# ATSAMR34J17B device description
Architecture: CORTEX-M0PLUS; Family: SAMR; Series: SAMR34
Registers are 32-bit, read-write, reset 0x0 unless marked. A register's access mark holds for its fields unless they carry their own. Offsets are from the block's base; [hi:lo] are bit positions; {n}, {i} and the like mark numbered series.

## PAC — Peripheral Access Controller
Instances: PAC 0x44000000
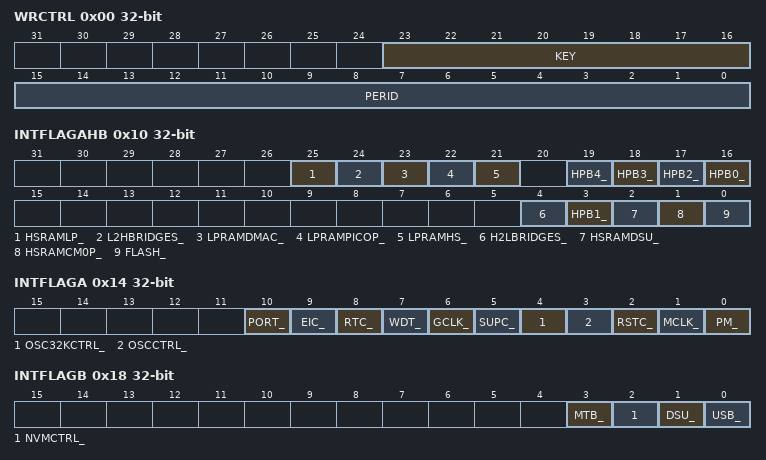
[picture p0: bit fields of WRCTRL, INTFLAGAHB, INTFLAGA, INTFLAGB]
0x00 WRCTRL — Write control
  [23:16] KEY — Peripheral access control key
    0=OFF (No action); 1=CLR (Clear protection); 2=SET (Set protection); 3=SETLCK (Set and lock protection)
  [15:0] PERID — Peripheral identifier
0x04 EVCTRL 8-bit — Event control
  [0] ERREO — Peripheral acess error event output
0x08 INTENCLR 8-bit (atomic clear) — Interrupt enable clear
  [0] ERR — Peripheral access error interrupt disable
0x09 INTENSET 8-bit (atomic set) — Interrupt enable set
  [0] ERR — Peripheral access error interrupt enable
0x10 INTFLAGAHB (atomic clear) — Bridge interrupt flag status
  [25] HSRAMLP_, [24] L2HBRIDGES_, [23] LPRAMDMAC_, [22] LPRAMPICOP_, [21] LPRAMHS_, [19] HPB4_, [18] HPB3_, [17] HPB2_, [16] HPB0_, [4] H2LBRIDGES_, [3] HPB1_, [2] HSRAMDSU_, [1] HSRAMCM0P_, [0] FLASH_
0x14 INTFLAGA (atomic clear) — Peripheral interrupt flag status - Bridge A
  [10] PORT_, [9] EIC_, [8] RTC_, [7] WDT_, [6] GCLK_, [5] SUPC_, [4] OSC32KCTRL_, [3] OSCCTRL_, [2] RSTC_, [1] MCLK_, [0] PM_
0x18 INTFLAGB (atomic clear) — Peripheral interrupt flag status - Bridge B
  [3] MTB_, [2] NVMCTRL_, [1] DSU_, [0] USB_
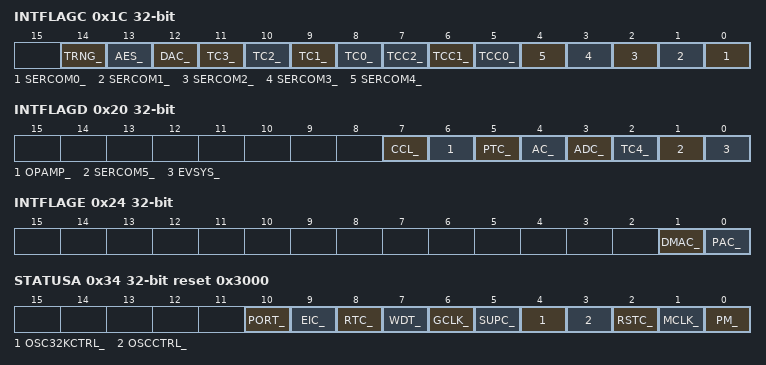
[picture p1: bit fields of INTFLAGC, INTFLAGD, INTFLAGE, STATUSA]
0x1C INTFLAGC (atomic clear) — Peripheral interrupt flag status - Bridge C
  [14] TRNG_, [13] AES_, [12] DAC_, [n+8] TC{n}_ (n=0..3), [7] TCC2_, [6] TCC1_, [5] TCC0_, [n] SERCOM{n}_ (n=0..4)
0x20 INTFLAGD (atomic clear) — Peripheral interrupt flag status - Bridge D
  [7] CCL_, [6] OPAMP_, [5] PTC_, [4] AC_, [3] ADC_, [2] TC4_, [1] SERCOM5_, [0] EVSYS_
0x24 INTFLAGE (atomic clear) — Peripheral interrupt flag status - Bridge E
  [1] DMAC_, [0] PAC_
0x34 STATUSA ro reset 0x3000 — Peripheral write protection status - Bridge A
  [10] PORT_ — PORT APB Protect Enable
  [9] EIC_ — EIC APB Protect Enable
  [8] RTC_ — RTC APB Protect Enable
  [7] WDT_ — WDT APB Protect Enable
  [6] GCLK_ — GCLK APB Protect Enable
  [5] SUPC_ — SUPC APB Protect Enable
  [4] OSC32KCTRL_ — OSC32KCTRL APB Protect Enable
  [3] OSCCTRL_ — OSCCTRL APB Protect Enable
  [2] RSTC_ — RSTC APB Protect Enable
  [1] MCLK_ — MCLK APB Protect Enable
  [0] PM_ — PM APB Protect Enable
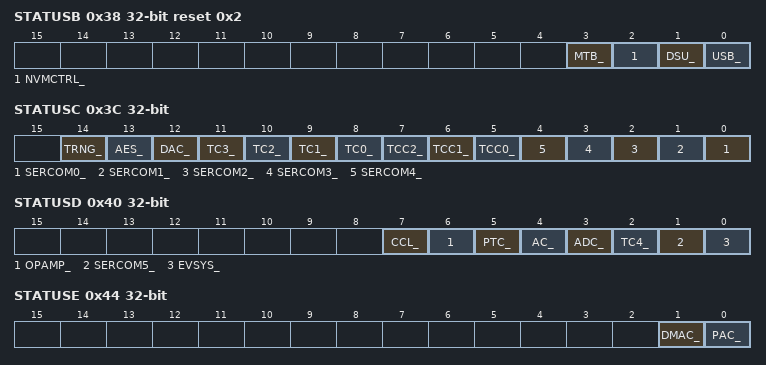
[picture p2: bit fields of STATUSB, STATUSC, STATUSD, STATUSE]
0x38 STATUSB ro reset 0x2 — Peripheral write protection status - Bridge B
  [3] MTB_ — MTB APB Protect Enable
  [2] NVMCTRL_ — NVMCTRL APB Protect Enable
  [1] DSU_ — DSU APB Protect Enable
  [0] USB_ — USB APB Protect Enable
0x3C STATUSC ro — Peripheral write protection status - Bridge C
  [14] TRNG_ — TRNG APB Protect Enable
  [13] AES_ — AES APB Protect Enable
  [12] DAC_ — DAC APB Protect Enable
  [n+8] TC{n}_ (n=0..3) — TC{n} APB Protect Enable
  [7] TCC2_ — TCC2 APB Protect Enable
  [6] TCC1_ — TCC1 APB Protect Enable
  [5] TCC0_ — TCC0 APB Protect Enable
  [n] SERCOM{n}_ (n=0..4) — SERCOM{n} APB Protect Enable
0x40 STATUSD ro — Peripheral write protection status - Bridge D
  [7] CCL_ — CCL APB Protect Enable
  [6] OPAMP_ — OPAMP APB Protect Enable
  [5] PTC_ — PTC APB Protect Enable
  [4] AC_ — AC APB Protect Enable
  [3] ADC_ — ADC APB Protect Enable
  [2] TC4_ — TC4 APB Protect Enable
  [1] SERCOM5_ — SERCOM5 APB Protect Enable
  [0] EVSYS_ — EVSYS APB Protect Enable
0x44 STATUSE ro — Peripheral write protection status - Bridge E
  [1] DMAC_ — DMAC APB Protect Enable
  [0] PAC_ — PAC APB Protect Enable

## PM — Power Manager
Instances: PM 0x40000000
0x00 CTRLA 8-bit — Control A
  [2] IORET — I/O Retention
0x01 SLEEPCFG 8-bit reset 0x2 — Sleep Configuration
  [2:0] SLEEPMODE
    2=IDLE (CPU, AHBx, and APBx clocks are OFF); 4=STANDBY (All Clocks are OFF); 5=BACKUP (Only Backup domain is powered ON); 6=OFF (All power domains are powered OFF)
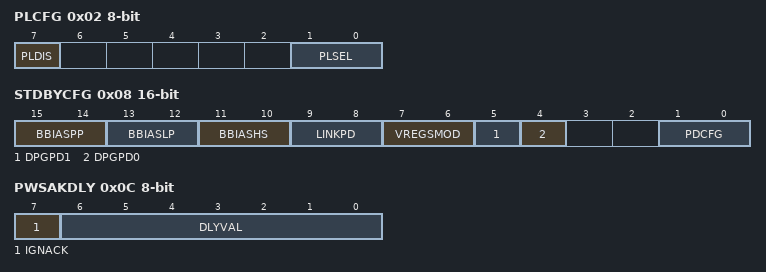
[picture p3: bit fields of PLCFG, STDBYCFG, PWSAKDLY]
0x02 PLCFG 8-bit — Performance Level Configuration
  [7] PLDIS — Performance Level Disable
  [1:0] PLSEL — Performance Level Select
    0=PL0 (Performance Level 0); 1=PL1 (Performance Level 1); 2=PL2 (Performance Level 2)
0x04 INTENCLR 8-bit (atomic clear) — Interrupt Enable Clear
  [0] PLRDY — Performance Level Interrupt Enable
0x05 INTENSET 8-bit (atomic set) — Interrupt Enable Set
  [0] PLRDY — Performance Level Ready interrupt Enable
0x06 INTFLAG 8-bit (atomic clear) — Interrupt Flag Status and Clear
  [0] PLRDY — Performance Level Ready
0x08 STDBYCFG 16-bit — Standby Configuration
  [15:14] BBIASPP — Back Bias for PicoPram
  [13:12] BBIASLP — Back Bias for HMCRAMCLP
  [11:10] BBIASHS — Back Bias for HMCRAMCHS
  [9:8] LINKPD — Linked Power Domain
    0=DEFAULT (Power domains are not linked); 1=PD01 (PD0 and PD1 power domains are linked); 2=PD12 (PD1 and PD2 power domains are linked); 3=PD012 (All power domains are linked)
  [7:6] VREGSMOD — Voltage Regulator Standby mode
    0=AUTO (Automatic mode); 1=PERFORMANCE (Performance oriented); 2=LP (Low Power oriented)
  [5] DPGPD1 — Dynamic Power Gating for PD1
  [4] DPGPD0 — Dynamic Power Gating for PD0
  [1:0] PDCFG — Power Domain Configuration
    0=DEFAULT (All power domains switching is handled by hardware.); 1=PD0 (PD0 is forced ACTIVE. PD1 and PD2 power domains switching is handled by hardware.); 2=PD01 (PD0 and PD1 are forced ACTIVE. PD2 power domain switching is handled by hardware.); 3=PD012 (All power domains are forced ACTIVE.)
0x0C PWSAKDLY 8-bit — Power Switch Acknowledge Delay
  [7] IGNACK — Ignore Acknowledge
  [6:0] DLYVAL — Delay Value
Value list PM_STDBYCFG__BBIASHS: 0=RETBB (Retention Back Biasing mode); 1=STDBYBB (Standby Back Biasing mode); 2=STDBYOFF (Standby OFF mode); 3=OFF (Always OFF mode)
